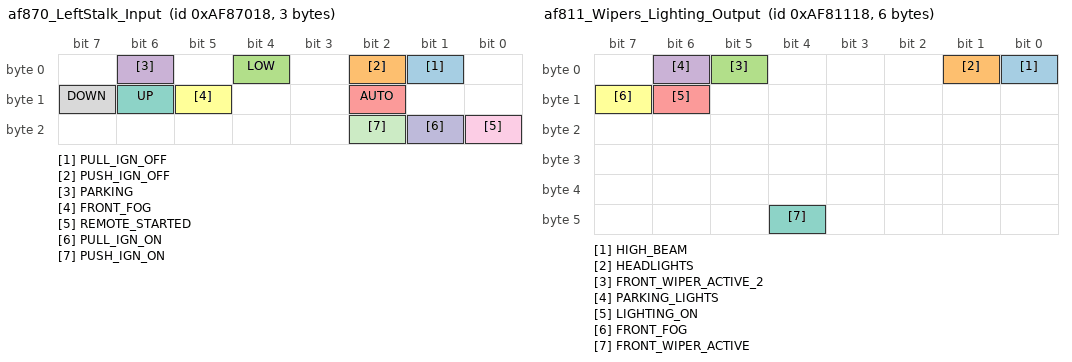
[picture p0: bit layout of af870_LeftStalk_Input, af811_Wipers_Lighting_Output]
BO_ 184053784 af870_LeftStalk_Input: 3 BCM
 SG_ PULL_IGN_OFF : 1|1@0+ (1,0) [0|0] "" XXX
 SG_ PUSH_IGN_OFF : 2|1@0+ (1,0) [0|0] "" XXX
 SG_ LOW : 4|1@0+ (1,0) [0|0] "" XXX
 SG_ PARKING : 6|1@0+ (1,0) [0|0] "" XXX
 SG_ AUTO : 10|1@0+ (1,0) [0|0] "" XXX
 SG_ FRONT_FOG : 13|1@0+ (1,0) [0|0] "" XXX
 SG_ UP : 14|1@0+ (1,0) [0|0] "" XXX
 SG_ DOWN : 15|1@0+ (1,0) [0|0] "" XXX
 SG_ REMOTE_STARTED : 16|1@0+ (1,0) [0|0] "" XXX
 SG_ PULL_IGN_ON : 17|1@0+ (1,0) [0|0] "" XXX
 SG_ PUSH_IGN_ON : 18|1@0+ (1,0) [0|0] "" XXX

BO_ 184029464 af811_Wipers_Lighting_Output: 6 BCM
 SG_ HIGH_BEAM : 0|1@0+ (1,0) [0|0] "" XXX
 SG_ HEADLIGHTS : 1|1@0+ (1,0) [0|0] "" XXX
 SG_ FRONT_WIPER_ACTIVE_2 : 5|1@0+ (1,0) [0|0] "" XXX
 SG_ PARKING_LIGHTS : 6|1@0+ (1,0) [0|0] "" XXX
 SG_ LIGHTING_ON : 14|1@0+ (1,0) [0|1] "" XXX
 SG_ FRONT_FOG : 15|1@0+ (1,0) [0|1] "" XXX
 SG_ FRONT_WIPER_ACTIVE : 44|1@0+ (1,0) [0|0] "" XXX

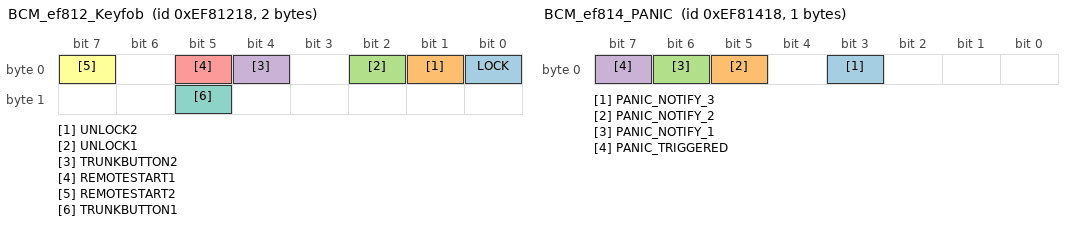
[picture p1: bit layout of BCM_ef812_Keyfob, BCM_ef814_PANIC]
BO_ 251138584 BCM_ef812_Keyfob: 2 XXX
 SG_ LOCK : 0|1@0+ (1,0) [0|0] "" XXX
 SG_ UNLOCK2 : 1|1@0+ (1,0) [0|0] "" XXX
 SG_ UNLOCK1 : 2|1@0+ (1,0) [0|0] "" XXX
 SG_ TRUNKBUTTON2 : 4|1@0+ (1,0) [0|0] "" XXX
 SG_ REMOTESTART1 : 5|1@0+ (1,0) [0|0] "" XXX
 SG_ REMOTESTART2 : 7|1@0+ (1,0) [0|0] "" XXX
 SG_ TRUNKBUTTON1 : 13|1@0+ (1,0) [0|0] "" XXX

BO_ 251139096 BCM_ef814_PANIC: 1 XXX
 SG_ PANIC_NOTIFY_3 : 3|1@0+ (1,0) [0|0] "" XXX
 SG_ PANIC_NOTIFY_2 : 5|1@0+ (1,0) [0|0] "" XXX
 SG_ PANIC_NOTIFY_1 : 6|1@0+ (1,0) [0|0] "" XXX
 SG_ PANIC_TRIGGERED : 7|1@0+ (1,0) [0|0] "" XXX

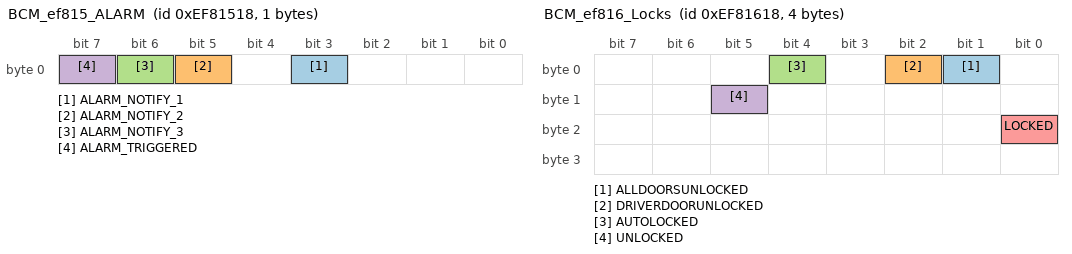
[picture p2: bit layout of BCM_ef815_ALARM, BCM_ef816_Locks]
BO_ 251139352 BCM_ef815_ALARM: 1 XXX
 SG_ ALARM_NOTIFY_1 : 3|1@0+ (1,0) [0|0] "" XXX
 SG_ ALARM_NOTIFY_2 : 5|1@0+ (1,0) [0|0] "" XXX
 SG_ ALARM_NOTIFY_3 : 6|1@0+ (1,0) [0|0] "" XXX
 SG_ ALARM_TRIGGERED : 7|1@0+ (1,0) [0|0] "" XXX

BO_ 251139608 BCM_ef816_Locks: 4 XXX
 SG_ ALLDOORSUNLOCKED : 1|1@0+ (1,0) [0|0] "" XXX
 SG_ DRIVERDOORUNLOCKED : 2|1@0+ (1,0) [0|0] "" XXX
 SG_ AUTOLOCKED : 4|1@0+ (1,0) [0|0] "" XXX
 SG_ UNLOCKED : 13|1@0+ (1,0) [0|0] "" XXX
 SG_ LOCKED : 16|1@0+ (1,0) [0|0] "" XXX

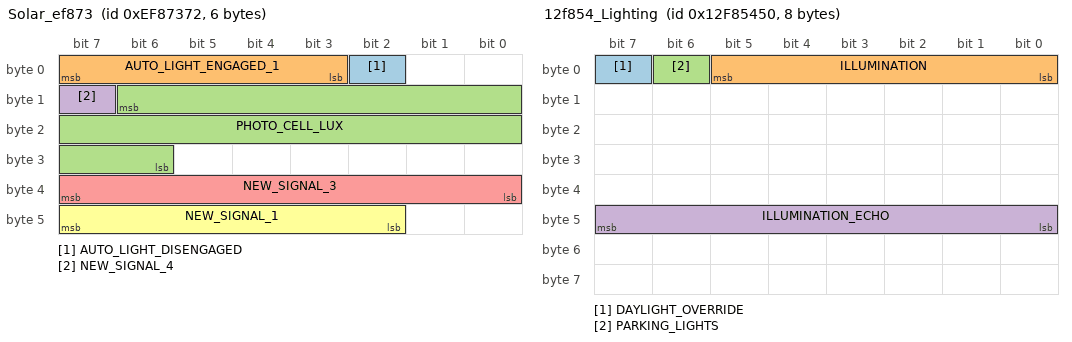
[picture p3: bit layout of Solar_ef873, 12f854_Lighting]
BO_ 251163506 Solar_ef873: 6 XXX
 SG_ AUTO_LIGHT_DISENGAGED : 2|1@0+ (1,0) [0|0] "" XXX
 SG_ AUTO_LIGHT_ENGAGED_1 : 7|5@0+ (1,0) [0|0] "" XXX
 SG_ PHOTO_CELL_LUX : 14|17@0+ (1,0) [0|0] "" XXX
 SG_ NEW_SIGNAL_4 : 15|1@0+ (1,0) [0|0] "" XXX
 SG_ NEW_SIGNAL_3 : 39|8@0+ (1,0) [0|0] "" XXX
 SG_ NEW_SIGNAL_1 : 47|6@0+ (1,0) [0|0] "" XXX

BO_ 318264400 12f854_Lighting: 8 Meter
 SG_ DAYLIGHT_OVERRIDE : 7|1@0+ (1,0) [0|1] "" XXX
 SG_ ILLUMINATION : 5|6@0+ (1,0) [0|0] "" XXX
 SG_ PARKING_LIGHTS : 6|1@0+ (1,0) [0|0] "" XXX
 SG_ ILLUMINATION_ECHO : 47|8@0+ (1,0) [0|0] "" XXX

BO_ 318246936 12f810_Lighting: 6 BCM
 SG_ NEW_SIGNAL_6 : 0|3@1+ (1,0) [0|0] "" XXX
 SG_ SET_TO_1_1 : 3|1@0+ (1,0) [0|0] "" XXX
 SG_ PEDAL_BRAKE_OUTPUT : 4|1@0+ (1,0) [0|0] "" XXX
 SG_ SET_TO_1_2 : 5|1@0+ (1,0) [0|0] "" XXX
 SG_ NEW_SIGNAL_7 : 7|2@0+ (1,0) [0|0] "" XXX
 SG_ NEW_SIGNAL_5 : 15|8@0+ (1,0) [0|0] "" XXX
 SG_ NEW_SIGNAL_3 : 18|3@0+ (1,0) [0|0] "" XXX
 SG_ RIGHTSIGNAL : 19|1@0+ (1,0) [0|0] "" XXX
 SG_ LEFTSIGNAL : 20|1@0+ (1,0) [0|0] "" XXX
 SG_ HAZARDS_ENABLE : 21|1@0+ (1,0) [0|0] "" XXX
 SG_ NEW_SIGNAL_4 : 22|1@0+ (1,0) [0|0] "" XXX
 SG_ SET_TO_1_3 : 23|1@0+ (1,0) [0|0] "" XXX
 SG_ NEW_SIGNAL_2 : 30|7@0+ (1,0) [0|0] "" XXX
 SG_ REVERSE : 31|1@0+ (1,0) [0|0] "" XXX
 SG_ NEW_SIGNAL_1 : 37|6@0+ (1,0) [0|0] "" XXX
 SG_ AUTORIGHT : 38|1@0+ (1,0) [0|0] "" XXX
 SG_ AUTOLEFT : 39|1@0+ (1,0) [0|0] "" XXX
 SG_ SET_TO_C0 : 47|8@0+ (1,0) [0|0] "" XXX

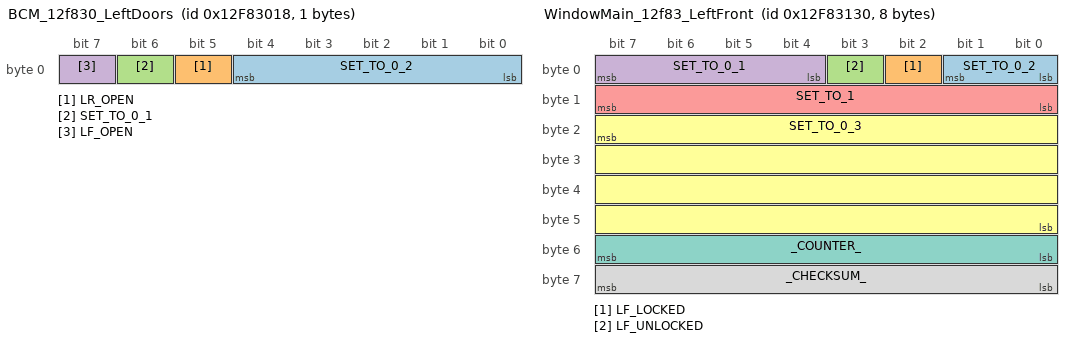
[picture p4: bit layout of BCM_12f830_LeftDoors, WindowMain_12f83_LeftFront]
BO_ 318255128 BCM_12f830_LeftDoors: 1 XXX
 SG_ SET_TO_0_2 : 4|5@0+ (1,0) [0|0] "" XXX
 SG_ LR_OPEN : 5|1@0+ (1,0) [0|0] "" XXX
 SG_ SET_TO_0_1 : 6|1@0+ (1,0) [0|0] "" XXX
 SG_ LF_OPEN : 7|1@0+ (1,0) [0|0] "" XXX

BO_ 318255408 WindowMain_12f83_LeftFront: 8 XXX
 SG_ SET_TO_0_2 : 0|2@1+ (1,0) [0|0] "" XXX
 SG_ LF_LOCKED : 2|1@0+ (1,0) [0|0] "" XXX
 SG_ LF_UNLOCKED : 3|1@0+ (1,0) [0|0] "" XXX
 SG_ SET_TO_0_1 : 7|4@0+ (1,0) [0|0] "" XXX
 SG_ SET_TO_1 : 15|8@0+ (1,0) [0|0] "" XXX
 SG_ SET_TO_0_3 : 23|32@0+ (1,0) [0|0] "" XXX
 SG_ _COUNTER_ : 48|8@1+ (1,0) [0|0] "" XXX
 SG_ _CHECKSUM_ : 56|8@1+ (1,0) [0|0] "" XXX

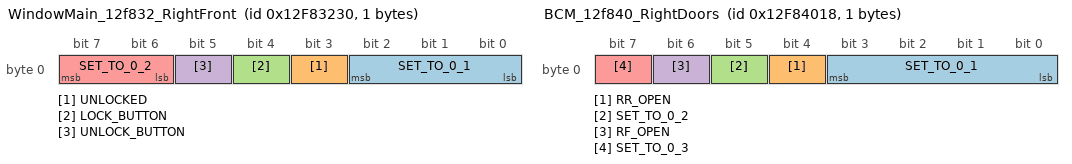
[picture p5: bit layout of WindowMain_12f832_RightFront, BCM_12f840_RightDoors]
BO_ 318255664 WindowMain_12f832_RightFront: 1 XXX
 SG_ SET_TO_0_1 : 0|3@1+ (1,0) [0|0] "" XXX
 SG_ UNLOCKED : 3|1@0+ (1,0) [0|0] "" XXX
 SG_ LOCK_BUTTON : 4|1@0+ (1,0) [0|0] "" XXX
 SG_ UNLOCK_BUTTON : 5|1@0+ (1,0) [0|0] "" XXX
 SG_ SET_TO_0_2 : 7|2@0+ (1,0) [0|0] "" XXX

BO_ 318259224 BCM_12f840_RightDoors: 1 XXX
 SG_ SET_TO_0_1 : 3|4@0+ (1,0) [0|0] "" XXX
 SG_ RR_OPEN : 4|1@0+ (1,0) [0|0] "" XXX
 SG_ SET_TO_0_2 : 5|1@0+ (1,0) [0|0] "" XXX
 SG_ RF_OPEN : 6|1@0+ (1,0) [0|0] "" XXX
 SG_ SET_TO_0_3 : 7|1@0+ (1,0) [0|0] "" XXX

BO_ 318259480 BCM_12f841_LeftRear: 1 XXX
 SG_ SET_TO_0_1 : 6|7@0+ (1,0) [0|0] "" XXX
 SG_ UNLOCKED : 7|1@0+ (1,0) [0|0] "" XXX

BO_ 318259736 BCM_12f842_RightRear: 1 XXX
 SG_ SET_TO_0_1 : 6|7@0+ (1,0) [0|0] "" XXX
 SG_ UNLOCKED : 7|1@0+ (1,0) [0|0] "" XXX

BO_ 318259992 BCM_12f843_Trunk: 1 XXX
 SG_ SET_TO_0_1 : 6|7@0+ (1,0) [0|0] "" XXX
 SG_ TRUNK_OPEN : 7|1@0+ (1,0) [0|0] "" XXX

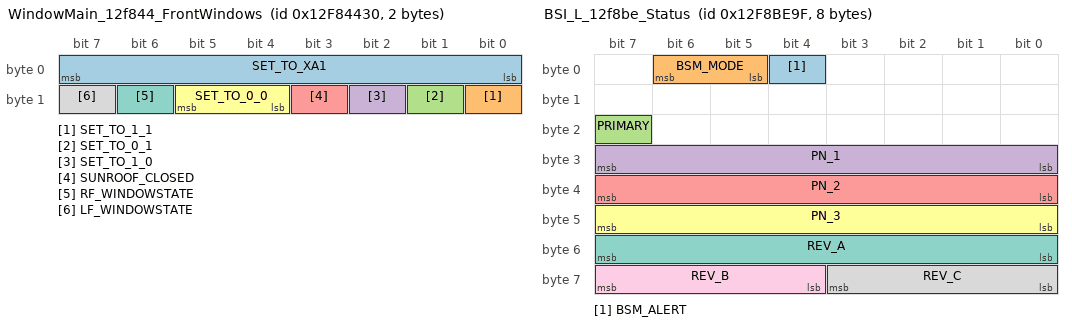
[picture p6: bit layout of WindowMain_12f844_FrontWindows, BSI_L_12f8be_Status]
BO_ 318260272 WindowMain_12f844_FrontWindows: 2 XXX
 SG_ SET_TO_XA1 : 7|8@0+ (1,0) [0|0] "" XXX
 SG_ SET_TO_1_1 : 8|1@0+ (1,0) [0|0] "" XXX
 SG_ SET_TO_0_1 : 9|1@0+ (1,0) [0|0] "" XXX
 SG_ SET_TO_1_0 : 10|1@0+ (1,0) [0|0] "" XXX
 SG_ SUNROOF_CLOSED : 11|1@0+ (1,0) [0|0] "" XXX
 SG_ SET_TO_0_0 : 13|2@0+ (1,0) [0|0] "" XXX
 SG_ RF_WINDOWSTATE : 14|1@0+ (1,0) [0|0] "" XXX
 SG_ LF_WINDOWSTATE : 15|1@0+ (1,0) [0|0] "" XXX

BO_ 318291615 BSI_L_12f8be_Status: 8 XXX
 SG_ BSM_ALERT : 4|1@0+ (1,0) [0|0] "" XXX
 SG_ BSM_MODE : 6|2@0+ (1,0) [0|0] "" XXX
 SG_ PRIMARY : 23|1@0+ (1,0) [0|0] "" XXX
 SG_ PN_1 : 31|8@0+ (1,0) [0|0] "" XXX
 SG_ PN_2 : 39|8@0+ (1,0) [0|0] "" XXX
 SG_ PN_3 : 47|8@0+ (1,0) [0|0] "" XXX
 SG_ REV_A : 55|8@0+ (1,0) [0|0] "" XXX
 SG_ REV_C : 59|4@0+ (1,0) [0|0] "" XXX
 SG_ REV_B : 63|4@0+ (1,0) [0|0] "" XXX

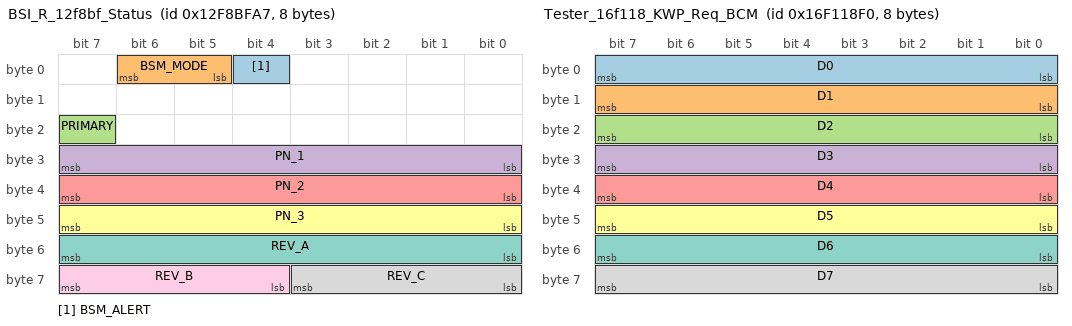
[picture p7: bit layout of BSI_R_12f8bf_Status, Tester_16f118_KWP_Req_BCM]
BO_ 318291879 BSI_R_12f8bf_Status: 8 XXX
 SG_ BSM_ALERT : 4|1@0+ (1,0) [0|0] "" XXX
 SG_ BSM_MODE : 6|2@0+ (1,0) [0|0] "" XXX
 SG_ PRIMARY : 23|1@0+ (1,0) [0|0] "" XXX
 SG_ PN_1 : 31|8@0+ (1,0) [0|0] "" XXX
 SG_ PN_2 : 39|8@0+ (1,0) [0|0] "" XXX
 SG_ PN_3 : 47|8@0+ (1,0) [0|0] "" XXX
 SG_ REV_A : 55|8@0+ (1,0) [0|0] "" XXX
 SG_ REV_C : 59|4@0+ (1,0) [0|0] "" XXX
 SG_ REV_B : 63|4@0+ (1,0) [0|0] "" XXX

BO_ 384899312 Tester_16f118_KWP_Req_BCM: 8 XXX
 SG_ D0 : 7|8@0+ (1,0) [0|0] "" XXX
 SG_ D1 : 15|8@0+ (1,0) [0|0] "" XXX
 SG_ D2 : 23|8@0+ (1,0) [0|0] "" XXX
 SG_ D3 : 31|8@0+ (1,0) [0|0] "" XXX
 SG_ D4 : 39|8@0+ (1,0) [0|0] "" XXX
 SG_ D5 : 47|8@0+ (1,0) [0|0] "" XXX
 SG_ D6 : 55|8@0+ (1,0) [0|0] "" XXX
 SG_ D7 : 63|8@0+ (1,0) [0|0] "" XXX

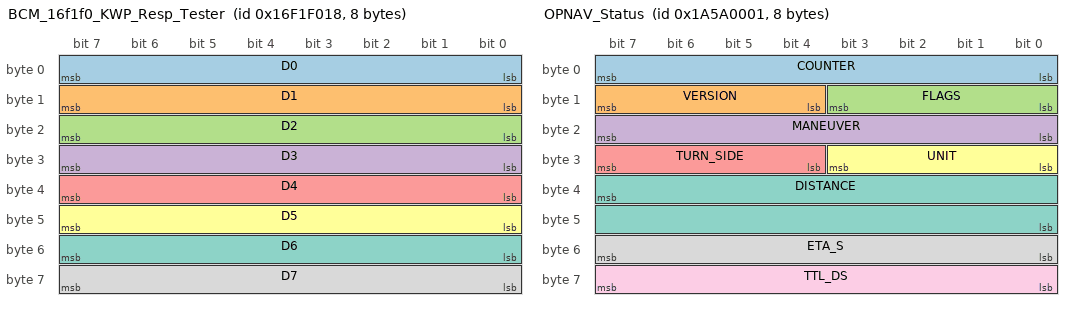
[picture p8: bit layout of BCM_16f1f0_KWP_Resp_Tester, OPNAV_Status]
BO_ 384954392 BCM_16f1f0_KWP_Resp_Tester: 8 XXX
 SG_ D0 : 7|8@0+ (1,0) [0|0] "" XXX
 SG_ D1 : 15|8@0+ (1,0) [0|0] "" XXX
 SG_ D2 : 23|8@0+ (1,0) [0|0] "" XXX
 SG_ D3 : 31|8@0+ (1,0) [0|0] "" XXX
 SG_ D4 : 39|8@0+ (1,0) [0|0] "" XXX
 SG_ D5 : 47|8@0+ (1,0) [0|0] "" XXX
 SG_ D6 : 55|8@0+ (1,0) [0|0] "" XXX
 SG_ D7 : 63|8@0+ (1,0) [0|0] "" XXX

 VAL_ 384954392 D0 127 "UNSUPPORTED" 112 "START_ACCEPTED" 96 "STOP_ACCEPTED" ;
BO_ 442105857 OPNAV_Status: 8 XXX
 SG_ COUNTER : 7|8@0+ (1,0) [0|255] "" XXX
 SG_ VERSION : 15|4@0+ (1,0) [0|15] "" XXX
 SG_ FLAGS : 11|4@0+ (1,0) [0|15] "" XXX
 SG_ MANEUVER : 23|8@0+ (1,0) [0|19] "" XXX
 SG_ TURN_SIDE : 31|4@0+ (1,0) [0|3] "" XXX
 SG_ UNIT : 27|4@0+ (1,0) [0|3] "" XXX
 SG_ DISTANCE : 39|16@0+ (1,0) [0|65535] "" XXX
 SG_ ETA_S : 55|8@0+ (1,0) [0|255] "" XXX
 SG_ TTL_DS : 63|8@0+ (1,0) [0|255] "" XXX

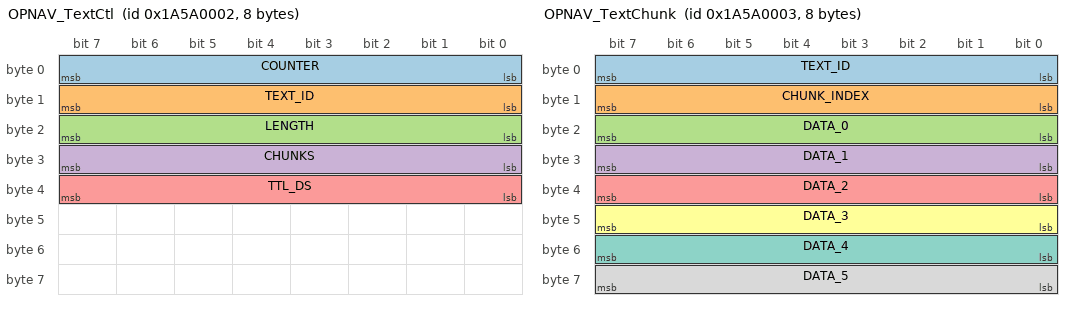
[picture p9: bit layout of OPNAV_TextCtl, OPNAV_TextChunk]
BO_ 442105858 OPNAV_TextCtl: 8 XXX
 SG_ COUNTER : 7|8@0+ (1,0) [0|255] "" XXX
 SG_ TEXT_ID : 15|8@0+ (1,0) [0|255] "" XXX
 SG_ LENGTH : 23|8@0+ (1,0) [0|36] "" XXX
 SG_ CHUNKS : 31|8@0+ (1,0) [0|6] "" XXX
 SG_ TTL_DS : 39|8@0+ (1,0) [0|255] "" XXX

BO_ 442105859 OPNAV_TextChunk: 8 XXX
 SG_ TEXT_ID : 7|8@0+ (1,0) [0|255] "" XXX
 SG_ CHUNK_INDEX : 15|8@0+ (1,0) [0|5] "" XXX
 SG_ DATA_0 : 23|8@0+ (1,0) [0|255] "" XXX
 SG_ DATA_1 : 31|8@0+ (1,0) [0|255] "" XXX
 SG_ DATA_2 : 39|8@0+ (1,0) [0|255] "" XXX
 SG_ DATA_3 : 47|8@0+ (1,0) [0|255] "" XXX
 SG_ DATA_4 : 55|8@0+ (1,0) [0|255] "" XXX
 SG_ DATA_5 : 63|8@0+ (1,0) [0|255] "" XXX

VAL_ 442105857 MANEUVER 0 "UNKNOWN" 1 "DEPART" 2 "NAME_CHANGE" 3 "SLIGHT_TURN" 4 "TURN" 5 "SHARP_TURN" 6 "U_TURN" 7 "ON_RAMP" 8 "OFF_RAMP" 9 "FORK" 10 "MERGE" 11 "ROUNDABOUT_ENTER" 12 "ROUNDABOUT_EXIT" 13 "ROUNDABOUT_ENTER_AND_EXIT" 14 "STRAIGHT" 16 "FERRY_BOAT" 17 "FERRY_TRAIN" 19 "DESTINATION" ;
VAL_ 442105857 TURN_SIDE 0 "NONE" 1 "LEFT" 2 "RIGHT" 3 "UNSPECIFIED" ;
VAL_ 442105857 UNIT 0 "METRES" 1 "FEET" 2 "MILES" 3 "KILOMETRES" ;

CM_ "OPNAV 0x1A5A0001/2/3: openpilot -> AAPI nav instructions on the 125 kbit/s B-CAN. Private ids; the head unit transmits its own 0x12F95xxx nav family and must not be mirrored. Status is sent at ~2 Hz and on change; FLAGS bit0 VALID, bit1 ARRIVED, bit2 ROUTE_ACTIVE. MANEUVER uses the Android Auto NextTurnEnum numbering (arrow only; this cluster has no turn-angle display). DISTANCE is in UNIT, ETA_S 0 = unknown, TTL_DS is the frame lifetime in 100 ms units (0 = clear). Text is up to 36 bytes in 6-byte chunks; TextCtl announces TEXT_ID/LENGTH/CHUNKS and chunks repeat the TEXT_ID plus index.";
CM_ BO_ 442105857 "openpilot nav status (B-CAN, private)";
CM_ BO_ 442105858 "openpilot nav road-name header (B-CAN, private)";
CM_ BO_ 442105859 "openpilot nav road-name chunk, 6 ASCII bytes (B-CAN, private)";
